# STM32G564xx register map
File version: 1.0
Registers are 32-bit, read-write, reset 0x0 unless marked. A register's access mark holds for its fields unless they carry their own. Offsets are from the block's base; [hi:lo] are bit positions; {n}, {i} and the like mark numbered series; 'fields as' and 'values as' point back to an identical list.

## GPDMA1 — DMA Controller (DMA)
Base 0x40020000
Same registers: GPDMA2 0x40021000
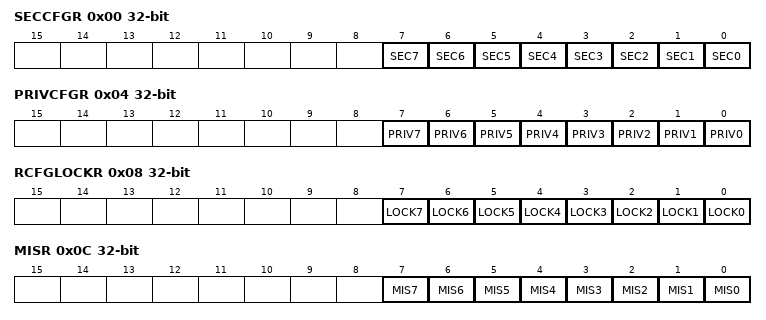
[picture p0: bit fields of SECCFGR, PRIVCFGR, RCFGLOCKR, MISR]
0x00 SECCFGR — DMA secure configuration register
  [n] SEC{n} (n=0..7) — secure state of channel {n}
0x04 PRIVCFGR — DMA privileged configuration register
  [n] PRIV{n} (n=0..7) — privileged state of channel {n}
0x08 RCFGLOCKR — DMA lock configuration register
  [n] LOCK{n} (n=0..7)
0x0C MISR ro — DMA non secure masked interrupt status register
  [n] MIS{n} (n=0..7) — masked interrupt status of channel {n}
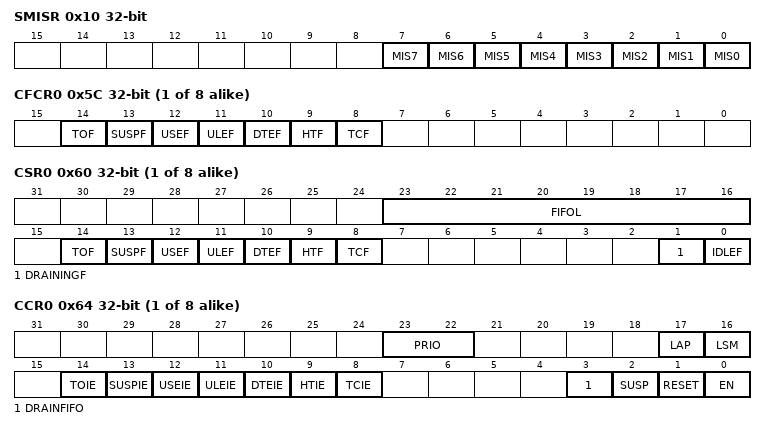
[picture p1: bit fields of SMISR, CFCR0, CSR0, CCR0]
0x10 SMISR ro — DMA secure masked interrupt status register
  [n] MIS{n} (n=0..7)
{0x50+0x80*i} CLBAR{i} (i=0..7) — DMA channel x linked-list base address register
  [31:16] LBA
{0x5C+0x80*i} CFCR{i} (i=0..7) — DMA channel x flag clear register
  [14] TOF — trigger overrun flag clear
  [13] SUSPF — completed suspension flag clear
  [12] USEF — user setting error flag clear
  [11] ULEF — update link transfer error flag clear
  [10] DTEF — data transfer error flag clear
  [9] HTF — half transfer flag clear
  [8] TCF — transfer complete flag clear
{0x60+0x80*i} CSR{i} ro (i=0..7) — DMA channel x flag status register
  [23:16] FIFOL — monitored FIFO level (in bytes)
  [14] TOF — trigger overrun flag
  [13] SUSPF — completed suspension flag
  [12] USEF — user setting error flag
  [11] ULEF — update link transfer error flag
  [10] DTEF — data transfer error flag
  [9] HTF — half transfer flag
  [8] TCF — transfer complete flag
  [1] DRAININGF — FIFO draining flag
  [0] IDLEF — idle flag
{0x64+0x80*i} CCR{i} (i=0..7) — DMA channel x control register
  [23:22] PRIO
  [17] LAP — linked-list allocated port
  [16] LSM — Link step mode
  [14] TOIE — trigger overrun interrupt enable
  [13] SUSPIE — completed suspension interrupt enable
  [12] USEIE — user setting error interrupt enable
  [11] ULEIE
  [10] DTEIE — data transfer error interrupt enable
  [9] HTIE — half transfer complete interrupt enable
  [8] TCIE — transfer complete interrupt enable
  [3] DRAINFIFO — empty FIFO
  [2] SUSP — suspend
  [1] RESET
  [0] EN — enable
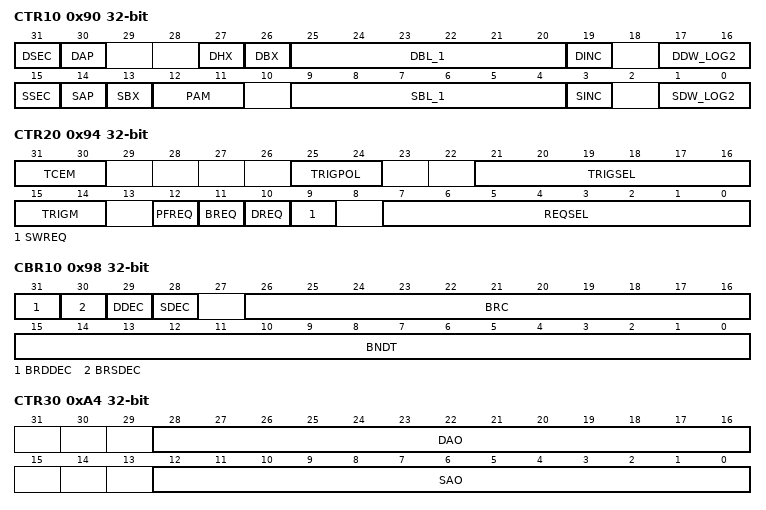
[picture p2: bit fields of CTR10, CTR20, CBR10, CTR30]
0x90 CTR10 — DMA channel x transfer register 1
  [31] DSEC
  [30] DAP — destination allocated port
  [27] DHX — destination half-word exchange
  [26] DBX — destination byte exchange
  [25:20] DBL_1
  [19] DINC — destination incrementing burst
  [17:16] DDW_LOG2
  [15] SSEC
  [14] SAP — source allocated port
  [13] SBX
  [12:11] PAM — padding/alignment mode
  [9:4] SBL_1
  [3] SINC — source incrementing burst
  [1:0] SDW_LOG2
0x94 CTR20 — DMA channel x transfer register 2
  [31:30] TCEM — transfer complete event mode
  [25:24] TRIGPOL — trigger event polarity
  [21:16] TRIGSEL — trigger event input selection
  [15:14] TRIGM — trigger mode
  [12] PFREQ
  [11] BREQ — Block hardware request
  [10] DREQ — destination hardware request
  [9] SWREQ — software request
  [7:0] REQSEL — DMA hardware request selection
0x98 CBR10 — DMA channel x block register 1
  [31] BRDDEC
  [30] BRSDEC — Block repeat source address decrement
  [29] DDEC — destination address decrement
  [28] SDEC — source address decrement
  [26:16] BRC — Block repeat counter
  [15:0] BNDT
{0x9C+0x80*i} CSAR{i} (i=0..7) — DMA channel x source address register
  [31:0] SA — source address
{0xA0+0x80*i} CDAR{i} (i=0..7) — DMA channel x destination address register
  [31:0] DA — destination address
0xA4 CTR30 — DMA channel x transfer register 3
  [28:16] DAO — destination address offset increment
  [12:0] SAO — source address offset increment
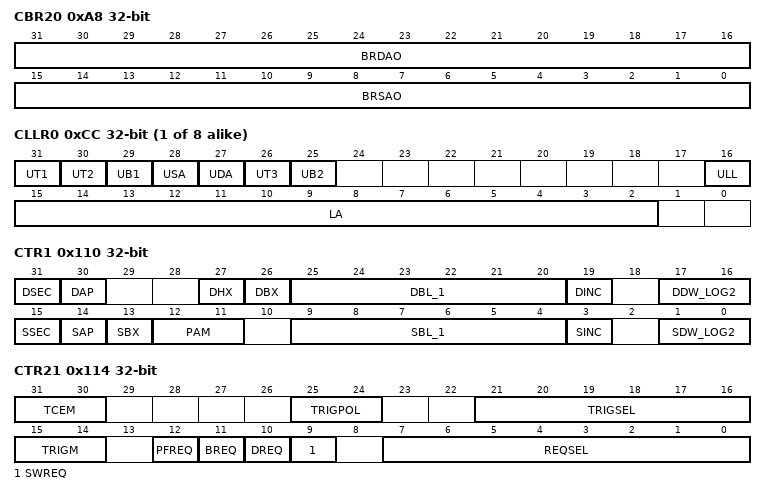
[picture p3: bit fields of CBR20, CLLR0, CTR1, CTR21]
0xA8 CBR20 — DMA channel x block register 2
  [31:16] BRDAO
  [15:0] BRSAO — Block repeated source address offset
{0xCC+0x80*i} CLLR{i} (i=0..7) — DMA channel x linked-list address register
  [31] UT1 — Update DMA_CxTR1 from memory
  [30] UT2 — Update DMA_CxTR2 from memory
  [29] UB1 — Update DMA_CxBR1 from memory
  [28] USA — update DMA_CxSAR from memory
  [27] UDA — Update DMA_CxDAR register from memory
  [26] UT3 — Update DMA_CxTR3 from memory
  [25] UB2 — Update DMA_CxBR2 from memory
  [16] ULL — Update DMA_CxLLR register from memory
  [15:2] LA
0x110 CTR1 — DMA channel x transfer register 1
  fields as CTR10
0x114 CTR21 — DMA channel x transfer register 2
  fields as CTR20
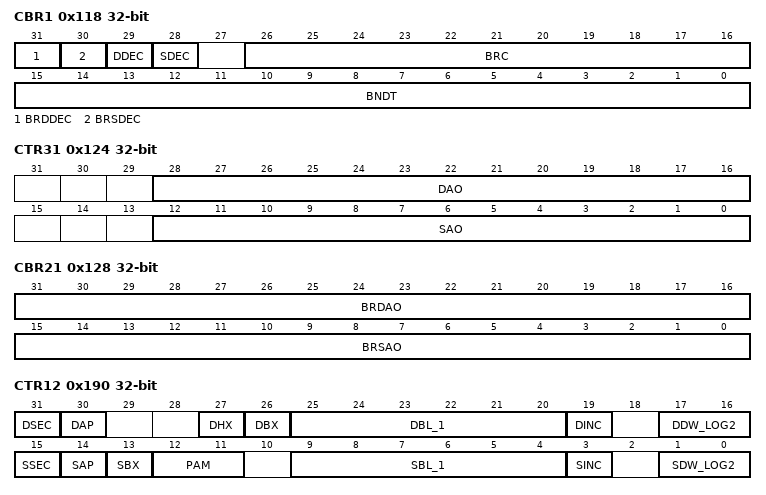
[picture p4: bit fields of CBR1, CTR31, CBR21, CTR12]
0x118 CBR1 — DMA channel x block register 1
  fields as CBR10
0x124 CTR31 — DMA channel x transfer register 3
  fields as CTR30
0x128 CBR21 — DMA channel x block register 2
  [31:16] BRDAO
  [15:0] BRSAO — Block repeated source address offset
0x190 CTR12 — DMA channel x transfer register 1
  fields as CTR10
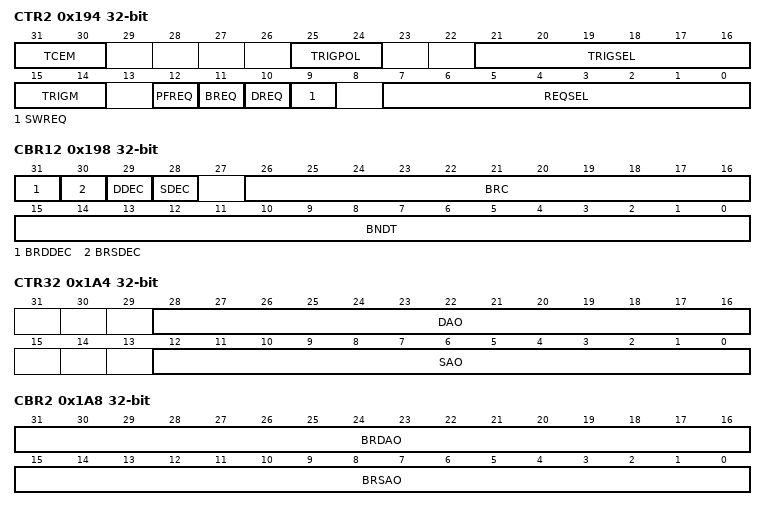
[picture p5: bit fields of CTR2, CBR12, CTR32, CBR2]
0x194 CTR2 — DMA channel x transfer register 2
  fields as CTR20
0x198 CBR12 — DMA channel x block register 1
  fields as CBR10
0x1A4 CTR32 — DMA channel x transfer register 3
  fields as CTR30
0x1A8 CBR2 — DMA channel x block register 2
  [31:16] BRDAO
  [15:0] BRSAO — Block repeated source address offset
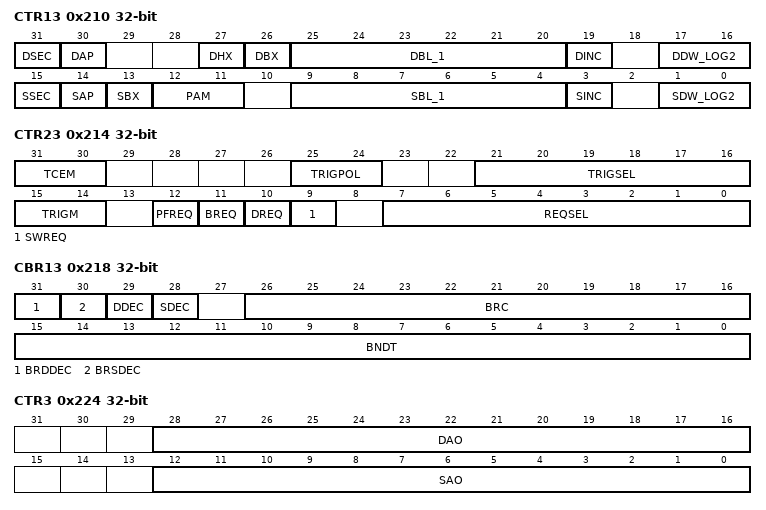
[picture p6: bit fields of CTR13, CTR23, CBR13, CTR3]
0x210 CTR13 — DMA channel x transfer register 1
  fields as CTR10
0x214 CTR23 — DMA channel x transfer register 2
  fields as CTR20
0x218 CBR13 — DMA channel x block register 1
  fields as CBR10
0x224 CTR3 — DMA channel x transfer register 3
  fields as CTR30
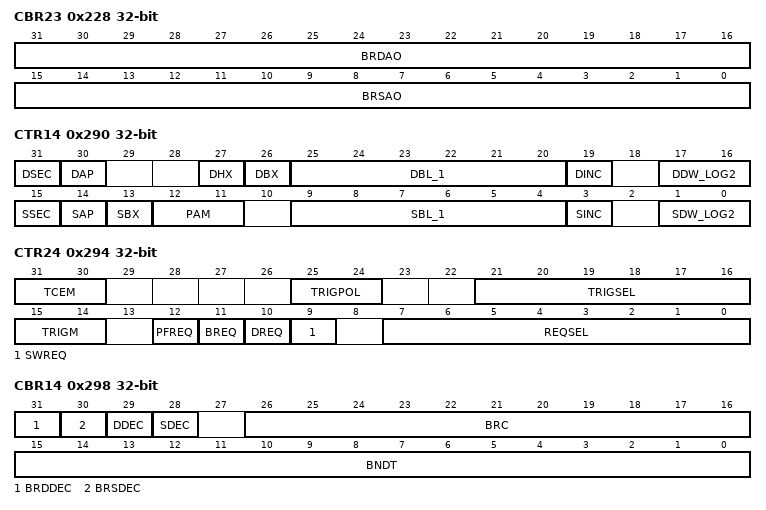
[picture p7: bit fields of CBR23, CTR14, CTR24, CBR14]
0x228 CBR23 — DMA channel x block register 2
  [31:16] BRDAO
  [15:0] BRSAO — Block repeated source address offset
0x290 CTR14 — DMA channel x transfer register 1
  fields as CTR10
0x294 CTR24 — DMA channel x transfer register 2
  fields as CTR20
0x298 CBR14 — DMA channel x block register 1
  fields as CBR10
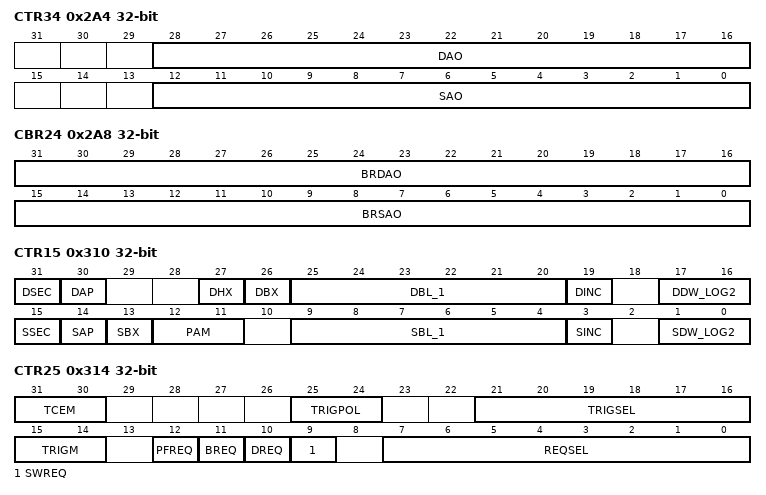
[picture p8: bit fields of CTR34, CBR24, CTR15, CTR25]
0x2A4 CTR34 — DMA channel x transfer register 3
  fields as CTR30
0x2A8 CBR24 — DMA channel x block register 2
  [31:16] BRDAO
  [15:0] BRSAO — Block repeated source address offset
0x310 CTR15 — DMA channel x transfer register 1
  fields as CTR10
0x314 CTR25 — DMA channel x transfer register 2
  fields as CTR20
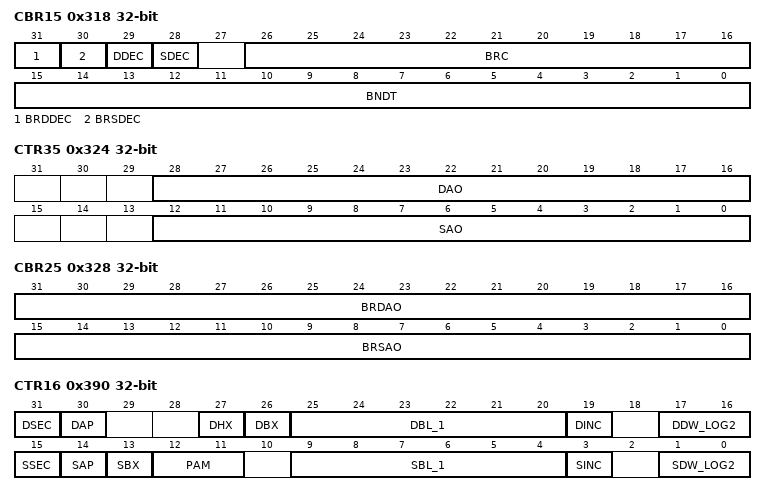
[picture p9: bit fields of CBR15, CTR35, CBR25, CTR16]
0x318 CBR15 — DMA channel x block register 1
  fields as CBR10
0x324 CTR35 — DMA channel x transfer register 3
  fields as CTR30
0x328 CBR25 — DMA channel x block register 2
  [31:16] BRDAO
  [15:0] BRSAO — Block repeated source address offset
0x390 CTR16 — DMA channel x transfer register 1
  fields as CTR10
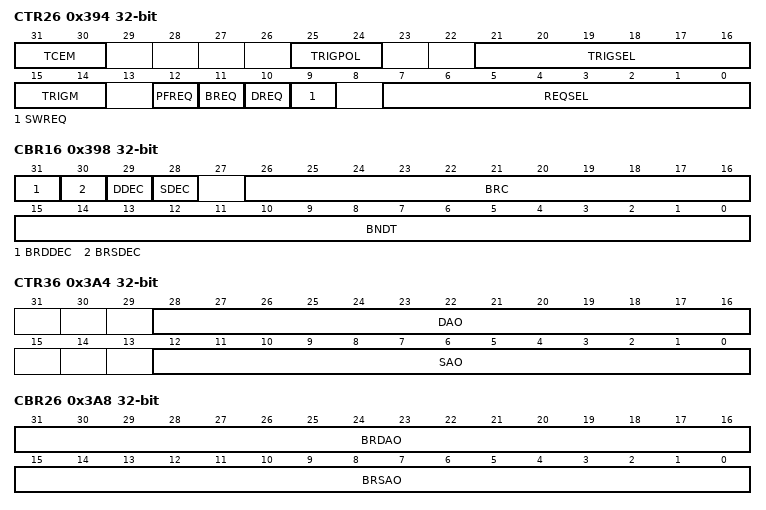
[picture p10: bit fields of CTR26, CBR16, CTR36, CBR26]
0x394 CTR26 — DMA channel x transfer register 2
  fields as CTR20
0x398 CBR16 — DMA channel x block register 1
  fields as CBR10
0x3A4 CTR36 — DMA channel x transfer register 3
  fields as CTR30
0x3A8 CBR26 — DMA channel x block register 2
  [31:16] BRDAO
  [15:0] BRSAO — Block repeated source address offset
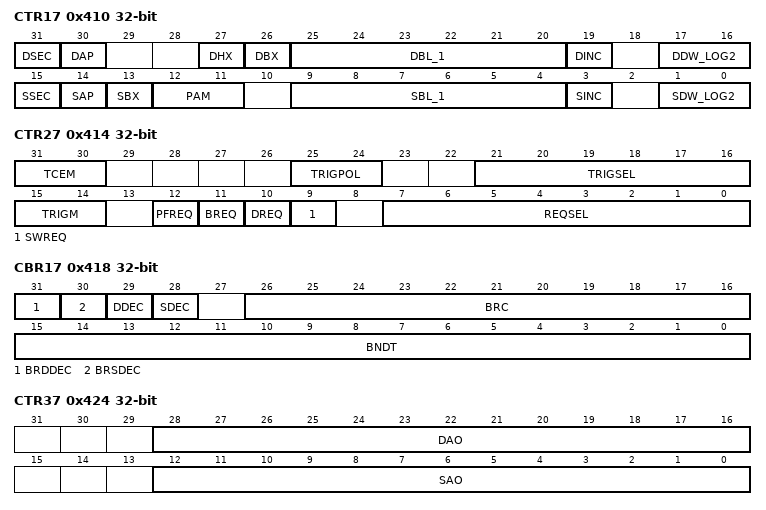
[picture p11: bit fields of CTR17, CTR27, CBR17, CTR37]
0x410 CTR17 — DMA channel x transfer register 1
  fields as CTR10
0x414 CTR27 — DMA channel x transfer register 2
  fields as CTR20
0x418 CBR17 — DMA channel x block register 1
  fields as CBR10
0x424 CTR37 — DMA channel x transfer register 3
  fields as CTR30
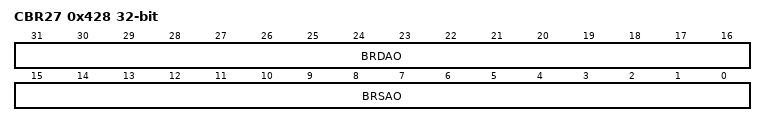
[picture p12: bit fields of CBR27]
0x428 CBR27 — DMA channel x block register 2
  [31:16] BRDAO
  [15:0] BRSAO — Block repeated source address offset
